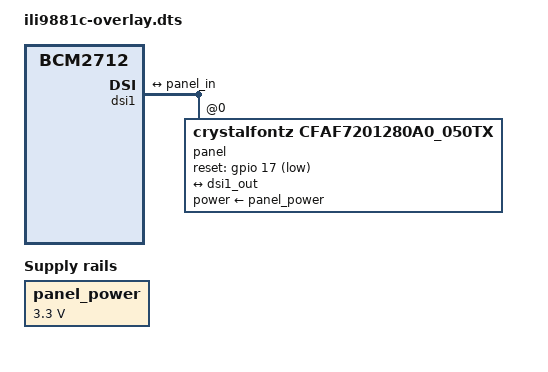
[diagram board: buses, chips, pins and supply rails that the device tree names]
/dts-v1/;
/plugin/;

/ {
    compatible = "brcm,bcm2712";

    fragment@0 {
        target = <&dsi1>;

        __overlay__ {
            status = "okay";
            #address-cells = <1>;
            #size-cells = <0>;

            panel@0 {
                compatible = "crystalfontz,cfaf7201280a0_050tx";
                reg = <0>;
                dsi,lanes = <4>;
                reset-gpios = <&gpio 17 1>;
                power-supply = <&panel_power>;

                port {
                    panel_in: endpoint {
                        remote-endpoint = <&dsi1_out>;
                    };
                };
            };

            port {
                dsi1_out: endpoint {
                    remote-endpoint = <&panel_in>;
                };
            };
        };
    };

    fragment@1 {
        target-path = "/";

        __overlay__ {
            panel_power: panel_power {
                compatible = "regulator-fixed";
                regulator-name = "panel_power";
                regulator-min-microvolt = <3300000>;
                regulator-max-microvolt = <3300000>;
                regulator-always-on;
            };
        };
    };
};
